# Template register map
Vendor: VendorName Co.Ltd; Series: SeriesName; File version: 1.2
CPU: CM7 r0p1, little endian, MPU, FPU, 4 interrupt priority bits
Registers are 32-bit, read-write, no defined reset value unless marked. A register's access mark holds for its fields unless they carry their own. Offsets are from the block's base; [hi:lo] are bit positions; {n}, {i} and the like mark numbered series.

## LIN1 — Local Interconnect Network 1
Base 0x40080000
Same registers: LIN2 0x40081000
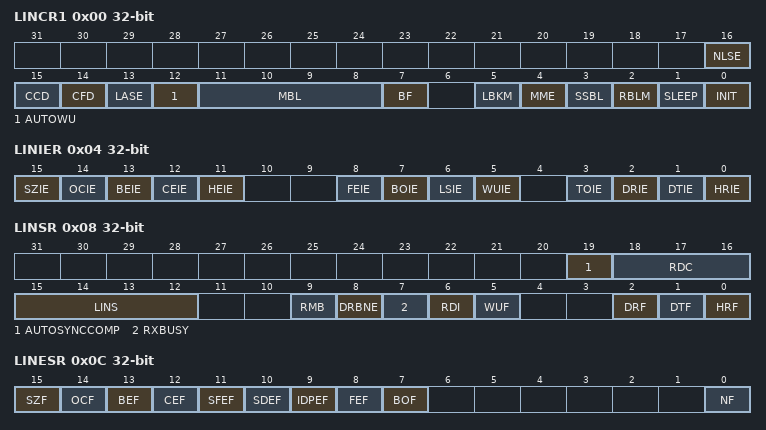
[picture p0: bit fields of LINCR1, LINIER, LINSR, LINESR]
0x00 LINCR1 — LIN control register 1
  [16] NLSE — LIN NLSE bit: LIN state capture enable on bit error
  [15] CCD — LIN CCD bit: checksum calculation disable
  [14] CFD — LIN CFD bit: checksum field disable
  [13] LASE — LIN LASE bit: LIN autosynchronization enable
  [12] AUTOWU — LIN AUTOWU bit: automatic wake-up
  [11:8] MBL — LIN MBL[3:0] bit: master break length
  [7] BF — LIN BF bit: bypass filter
  [5] LBKM — LIN LBKM bit: loop back mode
  [4] MME — LIN MME bit: master mode enable
  [3] SSBL — LIN SSBL bit: slave mode sync break length
  [2] RBLM — LIN RBLM bit: receiver buffer locked mode
  [1] SLEEP — LIN SLEEP bit: sleep mode request
  [0] INIT — LIN INIT bit: initialization mode request
0x04 LINIER — LIN interrupt enable register
  [15] SZIE — LIN SZIE bit: stuck at zero interrupt enable
  [14] OCIE — LIN OCIE bit: output compare interrupt enable
  [13] BEIE — LIN BEIE bit: bit error interrupt enable
  [12] CEIE — LIN CEIE bit: checksum error interrupt enable
  [11] HEIE — LIN HEIE bit: header error interrupt enable
  [8] FEIE — LIN FEIE bit: frame error interrupt enable
  [7] BOIE — LIN BOIE bit: buffer overrun interrupt enable
  [6] LSIE — LIN LSIE bit: LIN state interrupt enable
  [5] WUIE — LIN WUIE bit: wakeup interrupt enable
  [3] TOIE — LIN TOIE bit: timeout interrupt enable
  [2] DRIE — LIN DRIE bit: data reception complete interrupt enable
  [1] DTIE — LIN DTIE bit: data transmitted interrupt enable
  [0] HRIE — LIN HRIE bit: header received interrupt enable
0x08 LINSR — LIN status register
  [19] AUTOSYNCCOMP — LIN AUTOSYNCCOMP bit: autosynchronization complete
  [18:16] RDC ro — LIN RDC[2:0] bit: receive data byte count
  [15:12] LINS ro — LIN LINS[3:0] bit: LIN state
  [9] RMB — LIN RMB bit: release message buffer
  [8] DRBNE — LIN DRBNE bit: data reception buffer not empty flag
  [7] RXBUSY ro — LIN RXBUSY bit: receiver busy flag
  [6] RDI ro — LIN RDI bit: receiver data input
  [5] WUF — LIN WUF bit: wakeup flag
  [2] DRF — LIN DRF bit: data reception completed flag
  [1] DTF — LIN DTF bit: data transmission completed flag
  [0] HRF — LIN HRF bit: header received flag
0x0C LINESR — LIN error status register
  [15] SZF — LIN SZF bit: stuck at zero flag
  [14] OCF — LIN OCF bit: output compare flag
  [13] BEF — LIN BEF bit: bit error flag
  [12] CEF — LIN CEF bit: checksum error flag
  [11] SFEF — LIN SFEF bit: sync field error flag
  [10] SDEF — LIN SDEF bit: break delimiter error flag
  [9] IDPEF — LIN IDPEF bit: ID parity error flag
  [8] FEF — LIN FEF bit: framing error flag
  [7] BOF — LIN BOF bit: buffer overrun flag
  [0] NF — LIN NF bit: noise flag
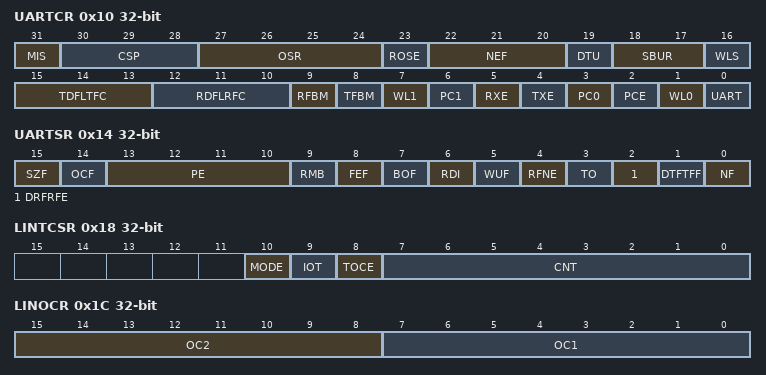
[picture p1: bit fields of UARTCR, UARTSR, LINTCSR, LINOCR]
0x10 UARTCR — LIN UART mode control register
  [31] MIS — LIN MIS bit: monitor idle state
  [30:28] CSP — LIN CSP[2:0] bit: configurable sample point
  [27:24] OSR — LIN OSR[3:0] bit: oversampling rate
  [23] ROSE — LIN ROSE bit: reduced oversampling enable
  [22:20] NEF — LIN NEF[2:0] bit: number of expected frames
  [19] DTU — LIN DTU bit: disable timeout in UART mode
  [18:17] SBUR — LIN SBUR[1:0] bit: number of stop bits in UART reception mode
  [16] WLS — LIN WLS bit: special word length in UART mode
  [15:13] TDFLTFC — LIN TDFLTFC[2:0] bit: transmitter data field length/Tx FIFO counter
  [12:10] RDFLRFC — LIN RDFLRFC[2:0] bit: receiver data field length/Rx FIFO counter
  [9] RFBM — LIN RFBM bit: Rx FIFO/buffer mode
  [8] TFBM — LIN TFBM bit: Tx FIFO/buffer mode
  [7] WL1 — LIN WL1 bit: word length in UART mode 1
  [6] PC1 — LIN PC1 bit: parity control 1
  [5] RXE — LIN RXE bit: receiver enable
  [4] TXE — LIN TXE bit: transmitter enable
  [3] PC0 — LIN PC0 bit: parity control 0
  [2] PCE — LIN PCE bit: parity control enable
  [1] WL0 — LIN WL0 bit: word length in UART mode 0
  [0] UART — LIN UART bit: UART mode enable
0x14 UARTSR — LIN UART mode status register
  [15] SZF — LIN SZF bit: stuck at zero flag
  [14] OCF — LIN OCF bit: output compare flag
  [13:10] PE — LIN PE[3:0] bit: parity error flag
  [9] RMB — LIN RMB bit: release message buffer
  [8] FEF — LIN FEF bit: framing error flag
  [7] BOF — LIN BOF bit: FIFO/buffer overrun flag
  [6] RDI ro — LIN RDI bit: receiver data input
  [5] WUF — LIN WUF bit: wakeup flag
  [4] RFNE ro — LIN RFNE bit: receive FIFO not empty
  [3] TO — LIN TO bit: timeout event enable
  [2] DRFRFE — LIN DRFRFE bit: data reception completed flag/Rx FIFO empty flag
  [1] DTFTFF — LIN DTFTFF bit: data transmission completed flag/Tx FIFO empty flag
  [0] NF — LIN NF bit: noise flag
0x18 LINTCSR — LIN timeout control status register
  [10] MODE — LIN MODE bit: timeout counter mode
  [9] IOT — LIN IOT bit: idle on timeout
  [8] TOCE — LIN TOCE bit: timeout counter enable
  [7:0] CNT ro — LIN CNT[7:0] bit: counter value
0x1C LINOCR — LIN output compare register
  [15:8] OC2 — LIN OC2[7:0] bit: output compare value 2
  [7:0] OC1 — LIN OC1[7:0] bit: output compare value 1
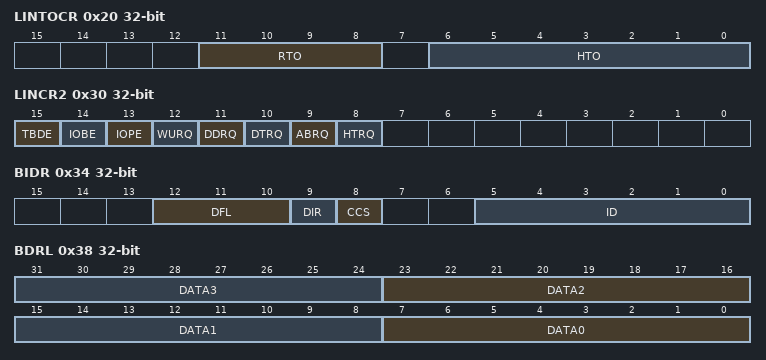
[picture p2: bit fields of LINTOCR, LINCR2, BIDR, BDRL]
0x20 LINTOCR — LIN timeout control register
  [11:8] RTO — LIN RTO[3:0] bit: response timeout value
  [6:0] HTO — LIN HTO[6:0] bit: header timeout value
0x24 LINFBRR — LIN fractional baud rate register
  [3:0] FBR — LIN FBR[3:0] bit: fractional baud rate
0x28 LINIBRR — LIN integer baud rate register
  [19:0] IBR — LIN IBR[19:0] bit: integer baud rate
0x2C LINCFR — LIN checksum field register
  [7:0] CF — LIN CF[7:0] bit: checksum bits
0x30 LINCR2 — LIN control register 2
  [15] TBDE — LIN TBDE bit: two-bit delimiter enable
  [14] IOBE — LIN IOBE bit: idle on bit error
  [13] IOPE — LIN IOPE bit: idle on identifier parity error
  [12] WURQ — LIN WURQ bit: wakeup generate request
  [11] DDRQ — LIN DDRQ bit: data discard request
  [10] DTRQ — LIN DTRQ bit: data transmission request
  [9] ABRQ — LIN ABRQ bit: abort request
  [8] HTRQ — LIN HTRQ bit: header transmission request
0x34 BIDR — LIN buffer identifier register
  [12:10] DFL — LIN DFL[2:0] bit: data field length
  [9] DIR — LIN DIR bit: control the transmission direction of the data segment
  [8] CCS — LIN CCS bit: classic checksum
  [5:0] ID — LIN ID[5:0] bit: identifier ID
0x38 BDRL — LIN buffer data register least significant
  [8n+7:8n] DATA{n} (n=0..3) — LIN DATA{n}[7:0] bit: data byte {n}
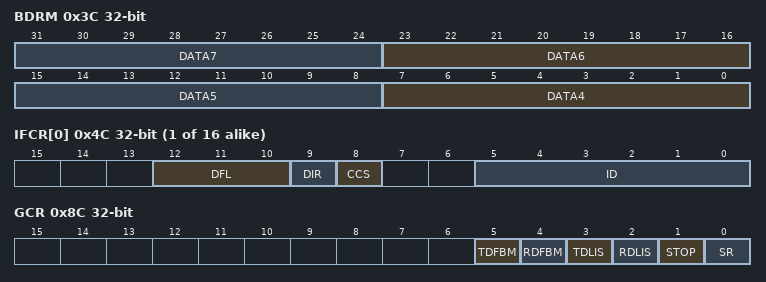
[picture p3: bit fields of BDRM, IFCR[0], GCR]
0x3C BDRM — LIN buffer data register most significant
  [8n-25:8n-32] DATA{n} (n=4..7) — LIN DATA{n}[7:0] bit: data byte {n}
0x40 IFER — LIN identifier filter enable register
  [15:0] FACT — LIN FACT[15:0] bit: filter active
0x44 IFMI ro — LIN identifier filter match index
  [4:0] IFMI — LIN IFMI[4:0] bit: filter match index
0x48 IFMR — LIN identifier filter mode register
  [7:0] IFM — LIN IFM[7:0] bit: filter mode
{0x4C+4i} IFCR[{i}] (i=0..15) — Grouping of TCD
  [12:10] DFL — LIN DFL[2:0] bit: data field length
  [9] DIR — LIN DIR bit: direction
  [8] CCS — LIN CCS bit: classic checksum
  [5:0] ID — LIN ID[5:0] bit: identifier
0x8C GCR — LIN global control register
  [5] TDFBM — LIN TDFBM bit: transmit data first bit MSB
  [4] RDFBM — LIN RDFBM bit: receive data first bit MSB
  [3] TDLIS — LIN TDLIS bit: transmit data level inversion selection
  [2] RDLIS — LIN RDLIS bit: received data level inversion selection
  [1] STOP — LIN STOP bit: one or two stop bit configuration
  [0] SR — LIN SR bit: soft reset
0x90 UARTPTO — LIN UART preset timeout register
  [11:0] PTO — LIN PTO[11:0] bit: preset timeout
0x94 UARTCTO ro — LIN UART current timeout register
  [11:0] CTO — LIN CTO[11:0] bit: current timeout
0x98 DMATXE — LIN DMA Tx enable register
  [0] DTE — LIN DTE bit: DMA Tx channel n enable
0x9C DMARXE — LIN DMA Rx enable register
  [0] DRE — LIN DRE bit: DMA Rx channel n enable
0x100 EXTHTRQ — LIN HTRQ enable control register
  [0] DMAHTRQEN — LIN DMAHTRQEN bit: DMA HTRQ enable
